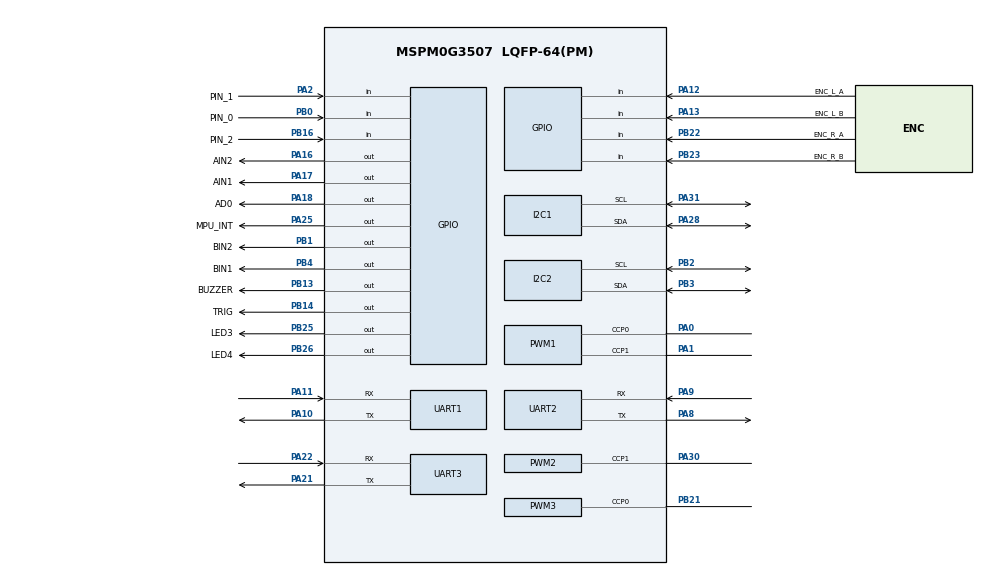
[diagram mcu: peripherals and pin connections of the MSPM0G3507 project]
/**
 * AI AGENTS: Do not edit this file directly. There is no validation or error feedback when
 * editing manually — mistakes will be silent until the file is loaded in SysConfig.
 * Use the SysConfig MCP server instead to make changes with immediate error reporting.
 *
 * These arguments were used when this file was generated. They will be automatically applied on subsequent loads
 * via the GUI or CLI. Run CLI with '--help' for additional information on how to override these arguments.
 * @cliArgs --device "MSPM0G350X" --part "Default" --package "LQFP-64(PM)" --product "mspm0_sdk@2.10.00.04"
 * @v2CliArgs --device "MSPM0G3507" --package "LQFP-64(PM)" --product "mspm0_sdk@2.10.00.04"
 * @versions {"tool":"1.28.0+4712"}
 */

/**
 * Import the modules used in this configuration.
 */
const CRC           = scripting.addModule("/ti/driverlib/CRC");
const DMA           = scripting.addModule("/ti/driverlib/DMA");
const GPIO          = scripting.addModule("/ti/driverlib/GPIO", {}, false);
const GPIO1         = GPIO.addInstance();
const GPIO2         = GPIO.addInstance();
const GPIO3         = GPIO.addInstance();
const GPIO4         = GPIO.addInstance();
const GPIO5         = GPIO.addInstance();
const GPIO6         = GPIO.addInstance();
const GPIO7         = GPIO.addInstance();
const GPIO8         = GPIO.addInstance();
const I2C           = scripting.addModule("/ti/driverlib/I2C", {}, false);
const I2C1          = I2C.addInstance();
const I2C2          = I2C.addInstance();
const PWM           = scripting.addModule("/ti/driverlib/PWM", {}, false);
const PWM1          = PWM.addInstance();
const PWM2          = PWM.addInstance();
const PWM3          = PWM.addInstance();
const SYSCTL        = scripting.addModule("/ti/driverlib/SYSCTL");
const SYSTICK       = scripting.addModule("/ti/driverlib/SYSTICK");
const TIMER         = scripting.addModule("/ti/driverlib/TIMER", {}, false);
const TIMER1        = TIMER.addInstance();
const UART          = scripting.addModule("/ti/driverlib/UART", {}, false);
const UART1         = UART.addInstance();
const UART2         = UART.addInstance();
const UART3         = UART.addInstance();
const ProjectConfig = scripting.addModule("/ti/project_config/ProjectConfig");

/**
 * Write custom configuration values to the imported modules.
 */
const divider6       = system.clockTree["PLL_CLK2X_DIV"];
divider6.divideValue = 4;

const divider9       = system.clockTree["UDIV"];
divider9.divideValue = 2;

const multiplier2         = system.clockTree["PLL_QDIV"];
multiplier2.multiplyValue = 5;

const mux8       = system.clockTree["HSCLKMUX"];
mux8.inputSelect = "HSCLKMUX_SYSPLL2X";


const Board = scripting.addModule("/ti/driverlib/Board", {}, false);

GPIO1.$name                         = "MOTOR_GPIO";
GPIO1.associatedPins.create(4);
GPIO1.associatedPins[0].$name       = "AIN1";
GPIO1.associatedPins[0].pin.$assign = "PA17";
GPIO1.associatedPins[1].$name       = "AIN2";
GPIO1.associatedPins[1].pin.$assign = "PA16";
GPIO1.associatedPins[2].$name       = "BIN1";
GPIO1.associatedPins[2].pin.$assign = "PB4";
GPIO1.associatedPins[3].$name       = "BIN2";
GPIO1.associatedPins[3].pin.$assign = "PB1";

GPIO2.$name                         = "LED_GPIO";
GPIO2.associatedPins.create(2);
GPIO2.associatedPins[0].$name       = "LED3";
GPIO2.associatedPins[0].pin.$assign = "PB25";
GPIO2.associatedPins[1].$name       = "LED4";
GPIO2.associatedPins[1].pin.$assign = "PB26";

GPIO3.$name                         = "BUZZER_GPIO";
GPIO3.associatedPins[0].$name       = "BUZZER";
GPIO3.associatedPins[0].pin.$assign = "PB13";

GPIO4.$name                         = "TRIG_GPIO";
GPIO4.associatedPins[0].$name       = "TRIG";
GPIO4.associatedPins[0].pin.$assign = "PB14";

GPIO5.$name                         = "KEY_GPIO";
GPIO5.associatedPins.create(3);
GPIO5.associatedPins[0].$name       = "PIN_0";
GPIO5.associatedPins[0].direction   = "INPUT";
GPIO5.associatedPins[0].pin.$assign = "PB0";
GPIO5.associatedPins[1].$name       = "PIN_1";
GPIO5.associatedPins[1].direction   = "INPUT";
GPIO5.associatedPins[1].pin.$assign = "PA2";
GPIO5.associatedPins[2].$name       = "PIN_2";
GPIO5.associatedPins[2].direction   = "INPUT";
GPIO5.associatedPins[2].pin.$assign = "PB16";

GPIO6.$name                         = "GRAY_SENSOR_GPIO";
GPIO6.associatedPins.create(4);
GPIO6.associatedPins[0].$name       = "AD0";
GPIO6.associatedPins[0].pin.$assign = "PA18";
GPIO6.associatedPins[1].$name       = "AD1";
GPIO6.associatedPins[2].$name       = "AD2";
GPIO6.associatedPins[3].$name       = "OUT";
GPIO6.associatedPins[3].direction   = "INPUT";

GPIO7.$name                         = "MPU_GPIO";
GPIO7.associatedPins[0].$name       = "MPU_INT";
GPIO7.associatedPins[0].pin.$assign = "PA25";

GPIO8.$name                         = "ENCODER_GPIO";
GPIO8.associatedPins.create(4);
GPIO8.associatedPins[0].$name       = "ENC_L_A";
GPIO8.associatedPins[0].direction   = "INPUT";
GPIO8.associatedPins[0].interruptEn = true;
GPIO8.associatedPins[0].polarity    = "RISE_FALL";
GPIO8.associatedPins[0].pin.$assign = "PA12";
GPIO8.associatedPins[1].$name       = "ENC_L_B";
GPIO8.associatedPins[1].direction   = "INPUT";
GPIO8.associatedPins[1].interruptEn = true;
GPIO8.associatedPins[1].polarity    = "RISE_FALL";
GPIO8.associatedPins[1].pin.$assign = "PA13";
GPIO8.associatedPins[2].$name       = "ENC_R_A";
GPIO8.associatedPins[2].direction   = "INPUT";
GPIO8.associatedPins[2].interruptEn = true;
GPIO8.associatedPins[2].polarity    = "RISE_FALL";
GPIO8.associatedPins[2].pin.$assign = "PB22";
GPIO8.associatedPins[3].$name       = "ENC_R_B";
GPIO8.associatedPins[3].direction   = "INPUT";
GPIO8.associatedPins[3].interruptEn = true;
GPIO8.associatedPins[3].polarity    = "RISE_FALL";
GPIO8.associatedPins[3].pin.$assign = "PB23";

I2C1.basicEnableController             = true;
I2C1.$name                             = "I2C_0_OLED";
I2C1.peripheral.sdaPin.$assign         = "PA28";
I2C1.peripheral.sclPin.$assign         = "PA31";
I2C1.sdaPinConfig.hideOutputInversion  = scripting.forceWrite(false);
I2C1.sdaPinConfig.onlyInternalResistor = scripting.forceWrite(false);
I2C1.sdaPinConfig.passedPeripheralType = scripting.forceWrite("Digital");
I2C1.sdaPinConfig.$name                = "ti_driverlib_gpio_GPIOPinGeneric1";
I2C1.sdaPinConfig.enableConfig         = true;
I2C1.sdaPinConfig.internalResistor     = "PULL_UP";
I2C1.sclPinConfig.hideOutputInversion  = scripting.forceWrite(false);
I2C1.sclPinConfig.onlyInternalResistor = scripting.forceWrite(false);
I2C1.sclPinConfig.passedPeripheralType = scripting.forceWrite("Digital");
I2C1.sclPinConfig.$name                = "ti_driverlib_gpio_GPIOPinGeneric2";
I2C1.sclPinConfig.enableConfig         = true;
I2C1.sclPinConfig.internalResistor     = "PULL_UP";

I2C2.$name                             = "I2C_1_MPU";
I2C2.peripheral.sdaPin.$assign         = "PB3";
I2C2.peripheral.sclPin.$assign         = "PB2";
I2C2.sdaPinConfig.$name                = "ti_driverlib_gpio_GPIOPinGeneric0";
I2C2.sdaPinConfig.hideOutputInversion  = scripting.forceWrite(false);
I2C2.sdaPinConfig.onlyInternalResistor = scripting.forceWrite(false);
I2C2.sdaPinConfig.passedPeripheralType = scripting.forceWrite("Digital");
I2C2.sclPinConfig.$name                = "ti_driverlib_gpio_GPIOPinGeneric3";
I2C2.sclPinConfig.hideOutputInversion  = scripting.forceWrite(false);
I2C2.sclPinConfig.onlyInternalResistor = scripting.forceWrite(false);
I2C2.sclPinConfig.passedPeripheralType = scripting.forceWrite("Digital");

PWM1.$name                              = "MOTOR_PWM";
PWM1.timerCount                         = 4000;
PWM1.peripheral.ccp0Pin.$assign         = "PA0";
PWM1.peripheral.ccp1Pin.$assign         = "PA1";
PWM1.PWM_CHANNEL_0.$name                = "ti_driverlib_pwm_MOTOR_PWMA";
PWM1.PWM_CHANNEL_0.ccValue              = 0;
PWM1.PWM_CHANNEL_1.$name                = "ti_driverlib_pwm_MOTOR_PWMB";
PWM1.PWM_CHANNEL_1.ccValue              = 0;
PWM1.ccp0PinConfig.$name                = "ti_driverlib_gpio_GPIOPinGeneric10";
PWM1.ccp0PinConfig.direction            = scripting.forceWrite("OUTPUT");
PWM1.ccp0PinConfig.hideOutputInversion  = scripting.forceWrite(false);
PWM1.ccp0PinConfig.onlyInternalResistor = scripting.forceWrite(false);
PWM1.ccp0PinConfig.passedPeripheralType = scripting.forceWrite("Digital");
PWM1.ccp1PinConfig.$name                = "ti_driverlib_gpio_GPIOPinGeneric11";
PWM1.ccp1PinConfig.direction            = scripting.forceWrite("OUTPUT");
PWM1.ccp1PinConfig.hideOutputInversion  = scripting.forceWrite(false);
PWM1.ccp1PinConfig.onlyInternalResistor = scripting.forceWrite(false);
PWM1.ccp1PinConfig.passedPeripheralType = scripting.forceWrite("Digital");

PWM2.$name                              = "SERVO_PWM_1";
PWM2.clockPrescale                      = 80;
PWM2.timerCount                         = 20000;
PWM2.ccIndex                            = [1];
PWM2.peripheral.$assign                 = "TIMG6";
PWM2.peripheral.ccp1Pin.$assign         = "PA30";
PWM2.PWM_CHANNEL_1.$name                = "ti_driverlib_pwm_SERVO_1";
PWM2.PWM_CHANNEL_1.ccValue              = 0;
PWM2.ccp1PinConfig.$name                = "ti_driverlib_gpio_GPIOPinGeneric13";
PWM2.ccp1PinConfig.direction            = scripting.forceWrite("OUTPUT");
PWM2.ccp1PinConfig.hideOutputInversion  = scripting.forceWrite(false);
PWM2.ccp1PinConfig.onlyInternalResistor = scripting.forceWrite(false);
PWM2.ccp1PinConfig.passedPeripheralType = scripting.forceWrite("Digital");

PWM3.$name                              = "SERVO_PWM_2";
PWM3.clockPrescale                      = 40;
PWM3.timerCount                         = 20000;
PWM3.ccIndex                            = [0];
PWM3.peripheral.$assign                 = "TIMG8";
PWM3.peripheral.ccp0Pin.$assign         = "PB21";
PWM3.PWM_CHANNEL_0.$name                = "ti_driverlib_pwm_SERVO_2";
PWM3.PWM_CHANNEL_0.ccValue              = 0;
PWM3.ccp0PinConfig.$name                = "ti_driverlib_gpio_GPIOPinGeneric14";
PWM3.ccp0PinConfig.direction            = scripting.forceWrite("OUTPUT");
PWM3.ccp0PinConfig.hideOutputInversion  = scripting.forceWrite(false);
PWM3.ccp0PinConfig.onlyInternalResistor = scripting.forceWrite(false);
PWM3.ccp0PinConfig.passedPeripheralType = scripting.forceWrite("Digital");

SYSCTL.clockTreeEn       = true;
SYSCTL.validateClkStatus = true;

TIMER1.$name              = "TIMER_0";
TIMER1.timerPeriod        = "1 ms";
TIMER1.peripheral.$assign = "TIMG0";

UART1.$name                      = "UART_0";
UART1.targetBaudRate             = 115200;
UART1.enabledDMARXTriggers       = "DL_UART_DMA_INTERRUPT_RX";
UART1.enabledDMATXTriggers       = "DL_UART_DMA_INTERRUPT_TX";
UART1.enableFIFO                 = true;
UART1.rxFifoThreshold            = "DL_UART_RX_FIFO_LEVEL_ONE_ENTRY";
UART1.txFifoThreshold            = "DL_UART_TX_FIFO_LEVEL_ONE_ENTRY";
UART1.enabledInterrupts          = ["BREAK_ERROR","DMA_DONE_RX","DMA_DONE_TX","EOT_DONE","FRAMING_ERROR","NOISE_ERROR","OVERRUN_ERROR","PARITY_ERROR"];
UART1.peripheral.rxPin.$assign   = "PA11";
UART1.peripheral.txPin.$assign   = "PA10";
UART1.txPinConfig.$name          = "ti_driverlib_gpio_GPIOPinGeneric7";
UART1.rxPinConfig.$name          = "ti_driverlib_gpio_GPIOPinGeneric8";
UART1.DMA_CHANNEL_RX.$name       = "DMA_CH0";
UART1.DMA_CHANNEL_RX.srcLength   = "BYTE";
UART1.DMA_CHANNEL_RX.addressMode = "f2b";
UART1.DMA_CHANNEL_RX.dstLength   = "BYTE";
UART1.DMA_CHANNEL_TX.$name       = "DMA_CH1";
UART1.DMA_CHANNEL_TX.addressMode = "b2f";
UART1.DMA_CHANNEL_TX.srcLength   = "BYTE";
UART1.DMA_CHANNEL_TX.dstLength   = "BYTE";

UART2.$name                    = "UART_1";
UART2.peripheral.rxPin.$assign = "PA9";
UART2.peripheral.txPin.$assign = "PA8";
UART2.txPinConfig.$name        = "ti_driverlib_gpio_GPIOPinGeneric4";
UART2.rxPinConfig.$name        = "ti_driverlib_gpio_GPIOPinGeneric5";

UART3.$name                    = "UART_2";
UART3.peripheral.rxPin.$assign = "PA22";
UART3.peripheral.txPin.$assign = "PA21";
UART3.txPinConfig.$name        = "ti_driverlib_gpio_GPIOPinGeneric6";
UART3.rxPinConfig.$name        = "ti_driverlib_gpio_GPIOPinGeneric9";

ProjectConfig.genLibCMSIS = true;

/**
 * Pinmux solution for unlocked pins/peripherals. This ensures that minor changes to the automatic solver in a future
 * version of the tool will not impact the pinmux you originally saw.  These lines can be completely deleted in order to
 * re-solve from scratch.
 */
CRC.peripheral.$suggestSolution                  = "CRC";
Board.peripheral.$suggestSolution                = "DEBUGSS";
Board.peripheral.swclkPin.$suggestSolution       = "PA20";
Board.peripheral.swdioPin.$suggestSolution       = "PA19";
GPIO6.associatedPins[1].pin.$suggestSolution     = "PB15";
GPIO6.associatedPins[2].pin.$suggestSolution     = "PA14";
GPIO6.associatedPins[3].pin.$suggestSolution     = "PB17";
I2C1.peripheral.$suggestSolution                 = "I2C0";
I2C2.peripheral.$suggestSolution                 = "I2C1";
PWM1.peripheral.$suggestSolution                 = "TIMA0";
PWM1.peripheral.ccp0Pin.$suggestSolution         = "PA0";
PWM1.peripheral.ccp1Pin.$suggestSolution         = "PA1";
PWM2.peripheral.$suggestSolution                 = "TIMG6";
PWM2.peripheral.ccp1Pin.$suggestSolution         = "PA30";
PWM3.peripheral.$suggestSolution                 = "TIMG8";
PWM3.peripheral.ccp0Pin.$suggestSolution         = "PB21";
TIMER1.peripheral.$suggestSolution               = "TIMG0";
UART1.peripheral.$suggestSolution                = "UART0";
UART1.DMA_CHANNEL_RX.peripheral.$suggestSolution = "DMA_CH1";
UART1.DMA_CHANNEL_TX.peripheral.$suggestSolution = "DMA_CH0";
UART2.peripheral.$suggestSolution                = "UART1";
UART3.peripheral.$suggestSolution                = "UART2";
